# f2837xd_dev_cfg_regs register map
Vendor: Texas Instruments
Peripheral module from a debugger description file (folder C2000).
Address unit: 16 bits
Registers are 32-bit, access not given, no defined reset value unless marked. A register's access mark holds for its fields unless they carry their own. Offsets are as the file gives them; lines under a group give offsets from that group; [hi:lo] are bit positions; {n}, {i} and the like mark numbered series; 'fields as' and 'values as' point back to an identical list; <NAME> marks a mode.

## DEV_CFG_REGS — DEV CFG Registers
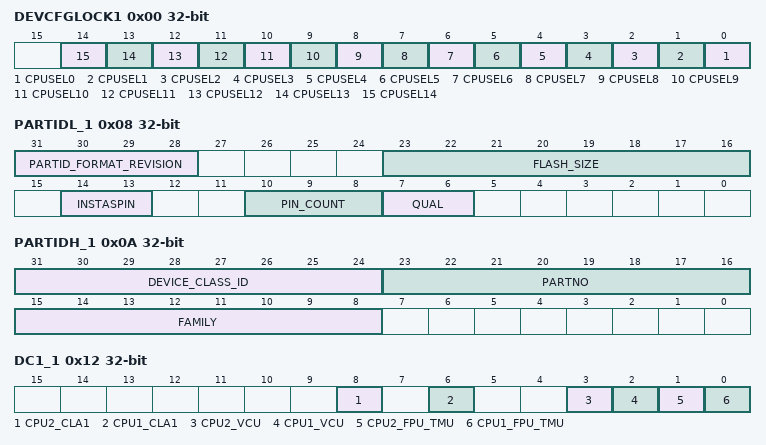
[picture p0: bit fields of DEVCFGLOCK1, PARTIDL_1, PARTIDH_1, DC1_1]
0x00 DEVCFGLOCK1 — Lock bit for CPUSELx registers
  [n] CPUSEL{n} (n=0..14) — Lock bit for CPUSEL{n} register (access R/SOnce)
0x08 PARTIDL_1 — Lower 32-bit of Device PART Identification Number
  [31:28] PARTID_FORMAT_REVISION — Revision of the PARTID format (access R/WOnce)
  [23:16] FLASH_SIZE — Flash size in KB (access R/WOnce)
  [14:13] INSTASPIN — Motorware feature set (access R/WOnce)
  [10:8] PIN_COUNT — Device Pin Count (access R/WOnce)
  [7:6] QUAL — Qualification Status (access R/WOnce)
0x0A PARTIDH_1 — Upper 32-bit of Device PART Identification Number
  [31:24] DEVICE_CLASS_ID — Device class ID (access R/WOnce)
  [23:16] PARTNO — Device part number (access R/WOnce)
  [15:8] FAMILY — Device family (access R/WOnce)
0x0C REVID ro — Device Revision Number
  [31:0] REVID — Device Revision ID
0x10 DC0_1 — Device Capability: Device Information
  [0] SINGLE_CORE — Single Core vs Dual Core (access R/WOnce)
0x12 DC1_1 — Device Capability: Processing Block Customization
  [8] CPU2_CLA1 — CPU2.CLA1 (access R/WOnce)
  [6] CPU1_CLA1 — CPU1.CLA1 (access R/WOnce)
  [3] CPU2_VCU — CPU2's VCU (access R/WOnce)
  [2] CPU1_VCU — CPU1's VCU (access R/WOnce)
  [1] CPU2_FPU_TMU — CPU2's FPU2+TMU2 (access R/WOnce)
  [0] CPU1_FPU_TMU — CPU1's FPU1+TMU1 (access R/WOnce)
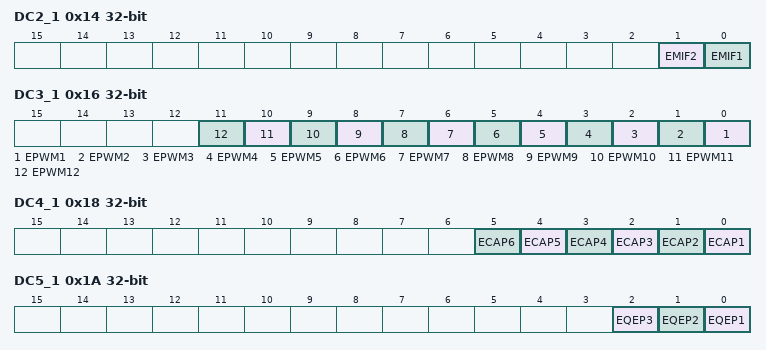
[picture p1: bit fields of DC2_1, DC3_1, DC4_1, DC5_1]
0x14 DC2_1 — Device Capability: EMIF Customization
  [1] EMIF2 — EMIF2 (access R/WOnce)
  [0] EMIF1 — EMIF1 (access R/WOnce)
0x16 DC3_1 — Device Capability: Peripheral Customization
  [n-1] EPWM{n} (n=1..12) — EPWM{n} (access R/WOnce)
0x18 DC4_1 — Device Capability: Peripheral Customization
  [n-1] ECAP{n} (n=1..6) — ECAP{n} (access R/WOnce)
0x1A DC5_1 — Device Capability: Peripheral Customization
  [2] EQEP3 — EQEP3 (access R/WOnce)
  [1] EQEP2 — EQEP2 (access R/WOnce)
  [0] EQEP1 — EQEP1 (access R/WOnce)
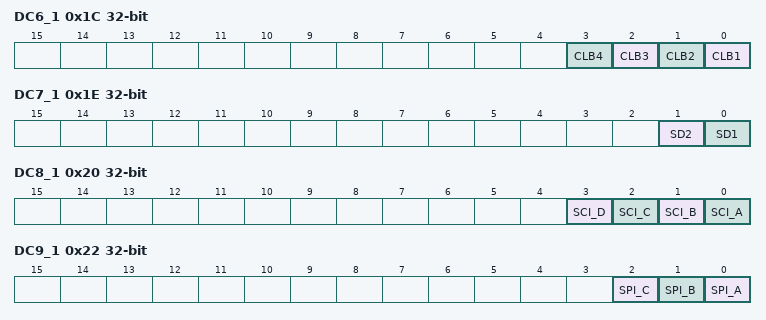
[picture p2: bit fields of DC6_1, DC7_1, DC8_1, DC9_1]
0x1C DC6_1 — Device Capability: Peripheral Customization
  [n-1] CLB{n} (n=1..4) — CLB{n} (access R/WOnce)
0x1E DC7_1 — Device Capability: Peripheral Customization
  [1] SD2 — SD2 (access R/WOnce)
  [0] SD1 — SD1 (access R/WOnce)
0x20 DC8_1 — Device Capability: Peripheral Customization
  [3] SCI_D — SCI_D (access R/WOnce)
  [2] SCI_C — SCI_C (access R/WOnce)
  [1] SCI_B — SCI_B (access R/WOnce)
  [0] SCI_A — SCI_A (access R/WOnce)
0x22 DC9_1 — Device Capability: Peripheral Customization
  [2] SPI_C — SPI_C (access R/WOnce)
  [1] SPI_B — SPI_B (access R/WOnce)
  [0] SPI_A — SPI_A (access R/WOnce)
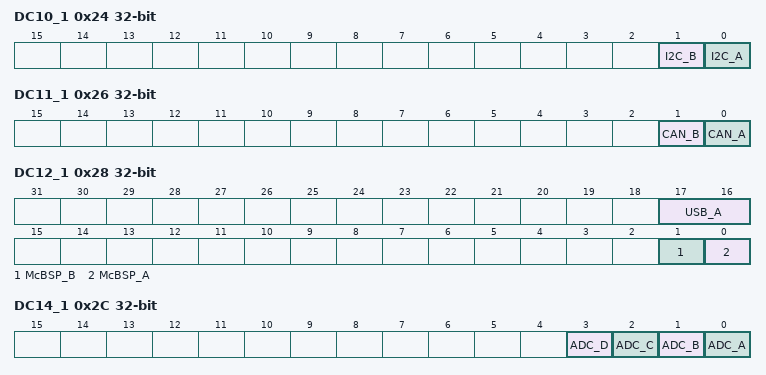
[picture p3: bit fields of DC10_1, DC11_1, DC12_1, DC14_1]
0x24 DC10_1 — Device Capability: Peripheral Customization
  [1] I2C_B — I2C_B (access R/WOnce)
  [0] I2C_A — I2C_A (access R/WOnce)
0x26 DC11_1 — Device Capability: Peripheral Customization
  [1] CAN_B — CAN_B (access R/WOnce)
  [0] CAN_A — CAN_A (access R/WOnce)
0x28 DC12_1 — Device Capability: Peripheral Customization
  [17:16] USB_A — Decides the capability of the USB_A Module (access R/WOnce)
  [1] McBSP_B — McBSP_B (access R/WOnce)
  [0] McBSP_A — McBSP_A (access R/WOnce)
0x2A DC13_1 — Device Capability: Peripheral Customization
  [0] uPP_A — uPP_A (access R/WOnce)
0x2C DC14_1 — Device Capability: Analog Modules Customization
  [3] ADC_D — ADC_D (access R/WOnce)
  [2] ADC_C — ADC_C (access R/WOnce)
  [1] ADC_B — ADC_B (access R/WOnce)
  [0] ADC_A — ADC_A (access R/WOnce)
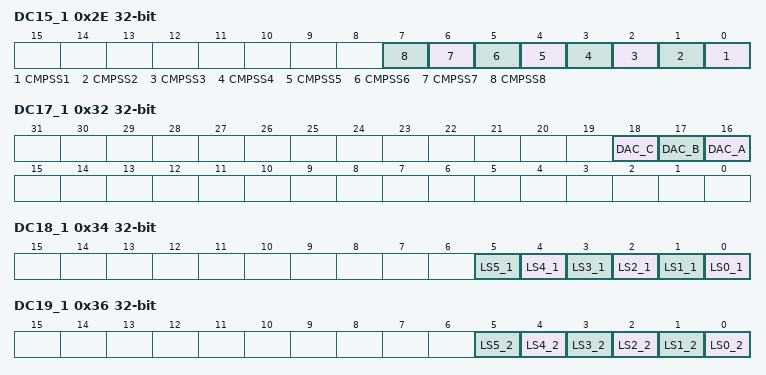
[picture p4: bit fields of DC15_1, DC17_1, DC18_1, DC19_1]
0x2E DC15_1 — Device Capability: Analog Modules Customization
  [n-1] CMPSS{n} (n=1..8) — CMPSS{n} (access R/WOnce)
0x32 DC17_1 — Device Capability: Analog Modules Customization
  [18] DAC_C — Buffered-DAC_C (access R/WOnce)
  [17] DAC_B — Buffered-DAC_B (access R/WOnce)
  [16] DAC_A — Buffered-DAC_A (access R/WOnce)
0x34 DC18_1 — Device Capability: CPU1 Lx SRAM Customization
  [n] LS{n}_1 (n=0..5) — LS{n}_1 (access R/WOnce)
0x36 DC19_1 — Device Capability: CPU2 Lx SRAM Customization
  [n] LS{n}_2 (n=0..5) — LS{n}_2 (access R/WOnce)
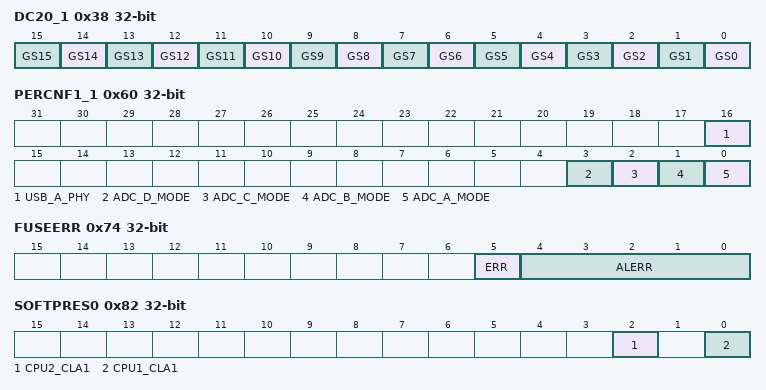
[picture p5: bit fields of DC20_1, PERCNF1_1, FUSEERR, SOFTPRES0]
0x38 DC20_1 — Device Capability: GSx SRAM Customization
  [n] GS{n} (n=0..15) — GS{n} (access R/WOnce)
0x60 PERCNF1_1 — Peripheral Configuration register
  [16] USB_A_PHY — USB_A_PHY (access R/WOnce)
  [3] ADC_D_MODE — ADC_D mode setting bit (access R/WOnce)
  [2] ADC_C_MODE — ADC_C mode setting bit (access R/WOnce)
  [1] ADC_B_MODE — ADC_B mode setting bit (access R/WOnce)
  [0] ADC_A_MODE — ADC_A mode setting bit (access R/WOnce)
0x74 FUSEERR ro — e-Fuse error Status register
  [5] ERR — Efuse Self Test Error Status
  [4:0] ALERR — Efuse Autoload Error Status
0x82 SOFTPRES0 rw — Processing Block Software Reset register
  [2] CPU2_CLA1 — CPU2_CLA1 software reset bit
  [0] CPU1_CLA1 — CPU1_CLA1 software reset bit
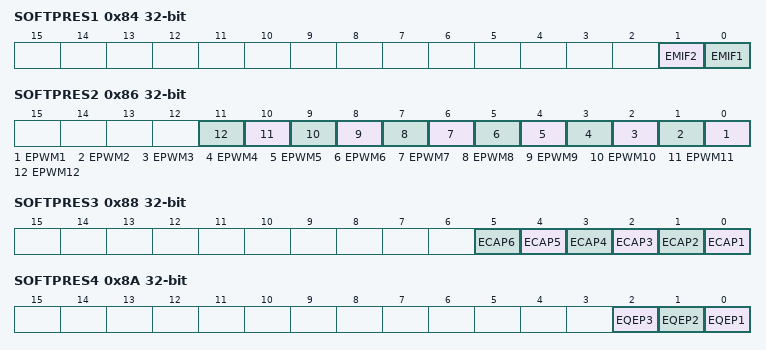
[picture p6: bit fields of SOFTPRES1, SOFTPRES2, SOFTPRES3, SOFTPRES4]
0x84 SOFTPRES1 rw — EMIF Software Reset register
  [1] EMIF2 — EMIF2 software reset bit
  [0] EMIF1 — EMIF1 software reset bit
0x86 SOFTPRES2 rw — Peripheral Software Reset register
  [n-1] EPWM{n} (n=1..12) — EPWM{n} software reset bit
0x88 SOFTPRES3 rw — Peripheral Software Reset register
  [n-1] ECAP{n} (n=1..6) — ECAP{n} software reset bit
0x8A SOFTPRES4 rw — Peripheral Software Reset register
  [2] EQEP3 — EQEP3 software reset bit
  [1] EQEP2 — EQEP2 software reset bit
  [0] EQEP1 — EQEP1 software reset bit
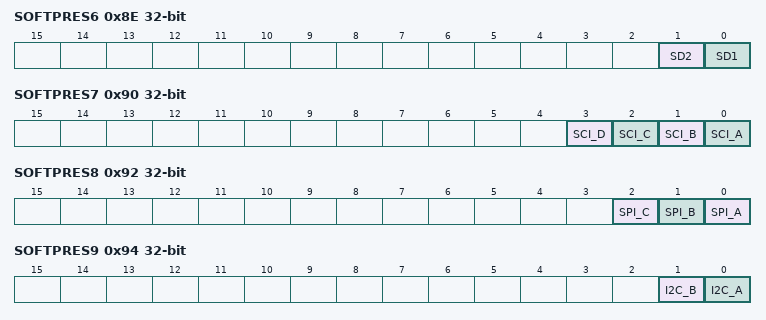
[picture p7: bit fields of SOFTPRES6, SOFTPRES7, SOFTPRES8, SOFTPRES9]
0x8E SOFTPRES6 rw — Peripheral Software Reset register
  [1] SD2 — SD2 software reset bit
  [0] SD1 — SD1 software reset bit
0x90 SOFTPRES7 rw — Peripheral Software Reset register
  [3] SCI_D — SCI_D software reset bit
  [2] SCI_C — SCI_C software reset bit
  [1] SCI_B — SCI_B software reset bit
  [0] SCI_A — SCI_A software reset bit
0x92 SOFTPRES8 rw — Peripheral Software Reset register
  [2] SPI_C — SPI_C software reset bit
  [1] SPI_B — SPI_B software reset bit
  [0] SPI_A — SPI_A software reset bit
0x94 SOFTPRES9 rw — Peripheral Software Reset register
  [1] I2C_B — I2C_B software reset bit
  [0] I2C_A — I2C_A software reset bit
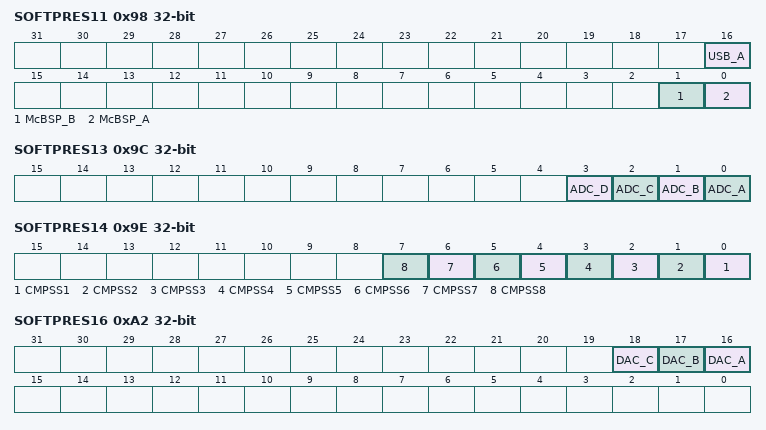
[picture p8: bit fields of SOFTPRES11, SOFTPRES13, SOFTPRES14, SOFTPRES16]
0x98 SOFTPRES11 rw — Peripheral Software Reset register
  [16] USB_A — USB_A software reset bit
  [1] McBSP_B — McBSP_B software reset bit
  [0] McBSP_A — McBSP_A software reset bit
0x9C SOFTPRES13 rw — Peripheral Software Reset register
  [3] ADC_D — ADC_D software reset bit
  [2] ADC_C — ADC_C software reset bit
  [1] ADC_B — ADC_B software reset bit
  [0] ADC_A — ADC_A software reset bit
0x9E SOFTPRES14 rw — Peripheral Software Reset register
  [n-1] CMPSS{n} (n=1..8) — CMPSS{n} software reset bit
0xA2 SOFTPRES16 rw — Peripheral Software Reset register
  [18] DAC_C — Buffered_DAC_C software reset bit
  [17] DAC_B — Buffered_DAC_B software reset bit
  [16] DAC_A — Buffered_DAC_A software reset bit
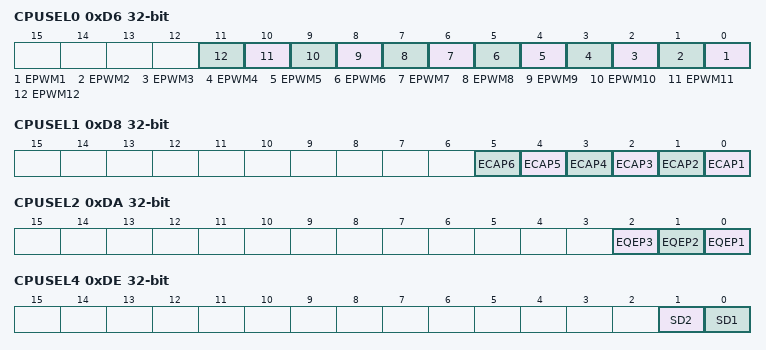
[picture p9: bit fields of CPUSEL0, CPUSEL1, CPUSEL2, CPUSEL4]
0xD6 CPUSEL0 rw — CPU Select register for common peripherals
  [n-1] EPWM{n} (n=1..12) — EPWM{n} CPU select bit
0xD8 CPUSEL1 rw — CPU Select register for common peripherals
  [n-1] ECAP{n} (n=1..6) — ECAP{n} CPU select bit
0xDA CPUSEL2 rw — CPU Select register for common peripherals
  [2] EQEP3 — EQEP3 CPU select bit
  [1] EQEP2 — EQEP2 CPU select bit
  [0] EQEP1 — EQEP1 CPU select bit
0xDC CPUSEL3 — CPU Select register for common peripherals
0xDE CPUSEL4 rw — CPU Select register for common peripherals
  [1] SD2 — SD2 CPU select bit
  [0] SD1 — SD1 CPU select bit
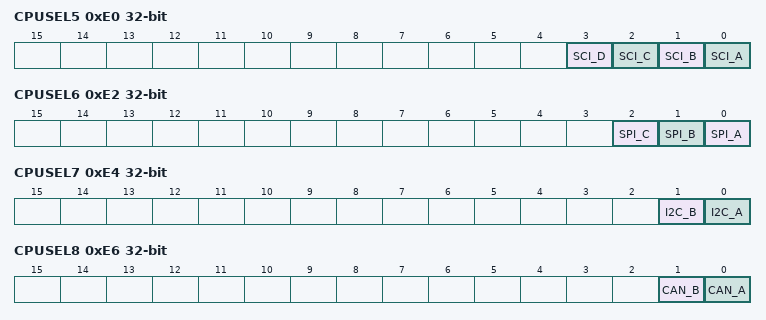
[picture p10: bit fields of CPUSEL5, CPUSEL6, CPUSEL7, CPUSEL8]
0xE0 CPUSEL5 rw — CPU Select register for common peripherals
  [3] SCI_D — SCI_D CPU select bit
  [2] SCI_C — SCI_C CPU select bit
  [1] SCI_B — SCI_B CPU select bit
  [0] SCI_A — SCI_A CPU select bit
0xE2 CPUSEL6 rw — CPU Select register for common peripherals
  [2] SPI_C — SPI_C CPU select bit
  [1] SPI_B — SPI_B CPU select bit
  [0] SPI_A — SPI_A CPU select bit
0xE4 CPUSEL7 rw — CPU Select register for common peripherals
  [1] I2C_B — I2C_B CPU select bit
  [0] I2C_A — I2C_A CPU select bit
0xE6 CPUSEL8 rw — CPU Select register for common peripherals
  [1] CAN_B — CAN_B CPU select bit
  [0] CAN_A — CAN_A CPU select bit
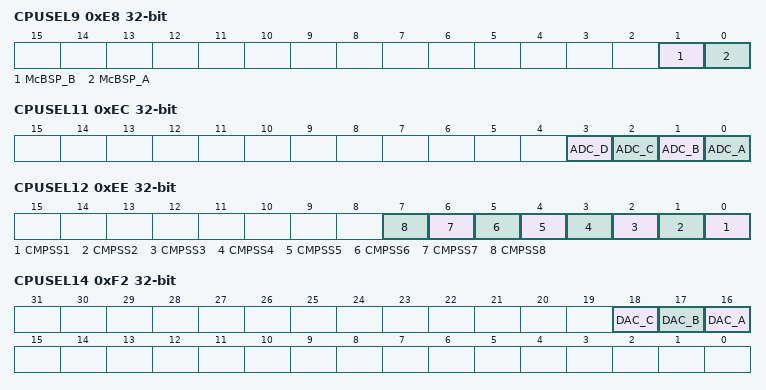
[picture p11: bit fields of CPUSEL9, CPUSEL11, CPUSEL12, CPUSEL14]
0xE8 CPUSEL9 rw — CPU Select register for common peripherals
  [1] McBSP_B — McBSP_B CPU select bit
  [0] McBSP_A — McBSP_A CPU select bit
0xEC CPUSEL11 rw — CPU Select register for common peripherals
  [3] ADC_D — ADC_D CPU select bit
  [2] ADC_C — ADC_C CPU select bit
  [1] ADC_B — ADC_B CPU select bit
  [0] ADC_A — ADC_A CPU select bit
0xEE CPUSEL12 rw — CPU Select register for common peripherals
  [n-1] CMPSS{n} (n=1..8) — CMPSS{n} CPU select bit
0xF2 CPUSEL14 rw — CPU Select register for common peripherals
  [18] DAC_C — Buffered_DAC_C CPU select bit
  [17] DAC_B — Buffered_DAC_B CPU select bit
  [16] DAC_A — Buffered_DAC_A CPU select bit
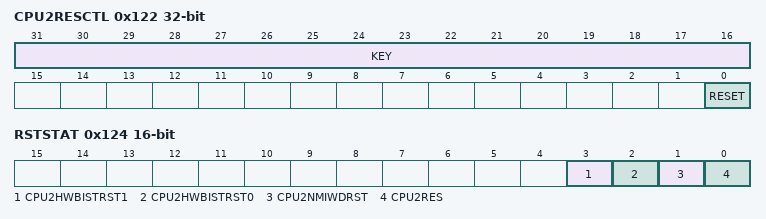
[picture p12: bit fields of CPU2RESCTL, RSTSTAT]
0x122 CPU2RESCTL — CPU2 Reset Control Register
  [31:16] KEY — Key Qualifier for writes to this register (access R=0/W)
  [0] RESET rw — CPU2 Reset Control bit
0x124 RSTSTAT 16-bit — Reset Status register for secondary C28x CPUs
  [3] CPU2HWBISTRST1 — Indicates whether a HWBIST reset was issued to CPU2 (access R/W=1)
  [2] CPU2HWBISTRST0 — Indicates whether a HWBIST reset was issued to CPU2 (access R/W=1)
  [1] CPU2NMIWDRST — Indicates whether a CPU2.NMIWD reset was issued to CPU2 (access R/W=1)
  [0] CPU2RES ro — CPU2 Reset Status bit
0x125 LPMSTAT 16-bit ro — LPM Status Register for secondary C28x CPUs
  [1:0] CPU2LPMSTAT — CPU2 LPM Status
0x12C SYSDBGCTL rw — System Debug Control register
  [0] BIT_0 — Used in PLL startup. Only reset by POR.
